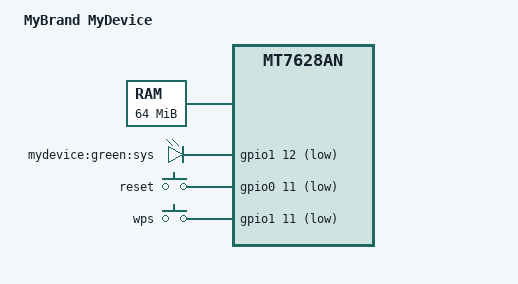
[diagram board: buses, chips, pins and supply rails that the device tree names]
/dts-v1/;

#include "mt7628an.dtsi"

/ {
    compatible = "mybrand,mydevice", "mediatek,mt7628an-soc";
    model = "MyBrand MyDevice";

    memory@0 {
        device_type = "memory";
        reg = <0x0 0x4000000>;  // 64MB RAM
    }

    chosen {
        bootargs = "console=ttyS0,115200";
    }

    flash@1f000000 {
        compatible = "jedec,spi-nor";
        reg = <0x1f000000 0x1000000>; // 16MB Flash
        bank-width = <2>;
        device-width = <1>;
        #address-cells = <1>;
        #size-cells = <1>;

        partitions {
            compatible = "fixed-partitions";
            #address-cells = <1>;
            #size-cells = <1>;

            partition@0 {
                label = "u-boot";
                reg = <0x0 0x30000>;
                read-only;
            };

            partition@30000 {
                label = "Config";
                reg = <0x30000 0x10000>;
            };

            partition@40000 {
                label = "factory";
                reg = <0x40000 0x10000>;
                read-only;
            };

            partition@50000 {
                label = "firmware";
                reg = <0x50000 0xfb0000>;
            };
        };
    };

    leds {
        compatible = "gpio-leds";

        sys {
            label = "mydevice:green:sys";
            gpios = <&gpio1 12 GPIO_ACTIVE_LOW>;
        };
    };

    keys {
        compatible = "gpio-keys";

        reset {
            label = "reset";
            gpios = <&gpio0 11 GPIO_ACTIVE_LOW>;
            linux,code = <KEY_RESTART>;
        };

        small_button {
            label = "wps";
            gpios = <&gpio1 11 GPIO_ACTIVE_LOW>;
            linux,code = <KEY_WPS>;
        };
    };
};
